# PIC32MK0512GPG048 device description
Architecture: MIPS; Family: PIC32MK; Series: PIC32MK
Registers are 32-bit, read-write, no defined reset value unless marked. A register's access mark holds for its fields unless they carry their own. Offsets are from the block's base; [hi:lo] are bit positions; {n}, {i} and the like mark numbered series.

## DMT
Instances: DMT 0x1f800e00 in periph_pb1_std
0x00 DMTCON — Deadman Timer Control Register
  [15] ON — Deadman Timer Module Enable bit
    1=Deadman Timer module is enabled; 0=Deadman Timer module is disabled
0x10 DMTPRECLR — Deadman Timer Preclear Register
  [15:8] STEP1 — Preclear Enable bits
    64=Enables the Deadman Timer Preclear (Step 1)
0x20 DMTCLR — Deadman Timer Clear Register
  [7:0] STEP2 — Clear Timer bits
    8=Clears STEP1
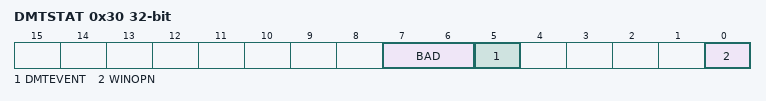
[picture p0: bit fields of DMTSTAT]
0x30 DMTSTAT ro — Deadman Timer Status Register
  [7:6] BAD — Bad STEP2 Value Detect bit
    3=Incorrect STEP1 value was detected/Incorrect STEP2 value was detected; 2=Incorrect STEP1 value was detected/Incorrect STEP2 value was not detected; 1=Incorrect STEP1 value was not detected/Incorrect STEP2 value was detected; 0=Incorrect STEP1 value was not detected/Incorrect STEP2 value was not detected
  [5] DMTEVENT — Deadman Timer Event bit
    1=Deadman timer event was detected (counter expired or bad STEP1 or STEP2 value was entered prior to counter increment); 0=Deadman timer even was not detected
  [0] WINOPN — Deadman Timer Clear Window bit
    1=Deadman timer clear window is open; 0=Deadman timer clear window is not open
0x40 DMTCNT ro — Deadman Timer Count Register
  [31:0] COUNTER
0x60 DMTPSCNT ro — Post Status Configure DMT Count Status Register
  [31:0] PSCNT
0x70 DMTPSINTV ro — Post Status Configure DMT Interval Status Register
  [31:0] PSINTV
Value list DMTSTAT__BAD1: 1=Incorrect STEP1 value was detected; 0=Incorrect STEP1 value was not detected

## DSCTRL
Instances: DSCTRL 0x1f8c0200 in periph_pb6_std
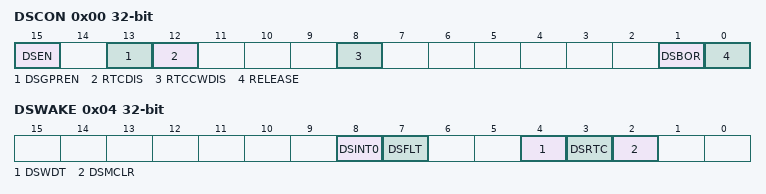
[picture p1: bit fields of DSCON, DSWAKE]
0x00 DSCON — Deep Sleep Control Register
  [15] DSEN — Deep Sleep Enable bit
    1=Deep Sleep mode is entered on a WAIT command; 0=Sleep mode is entered on a WAIT command
  [13] DSGPREN — General Purpose Registers Enable bit
    1=General purpose register retention is enabled in Deep Sleep mode; 0=No general purpose register retention in Deep Sleep mode
  [12] RTCDIS — RTCC Module Disable bit
    1=RTCC module is not enabled; 0=RTCC module is enabled
  [8] RTCCWDIS — RTCC Wake-up Disable bit
    1=Wake-up from RTCC is disabled; 0=Wake-up from RTCC is enabled
  [1] DSBOR — Deep Sleep BOR Event Status bit
    1=DSBOREN was enabled and VDD dropped below the DSBOR threshold during Deep Sleep; 0=DSBOREN was disabled, or VDD did not drop below the DSBOR threshold during Deep Sleep
  [0] RELEASE — I/O Pin State Release bit
    1=Upon waking from Deep Sleep, the I/O pins maintain their previous states; 0=Release I/O pins and allow their respective TRIS and LAT bits to control their states
0x04 DSWAKE — Deep Sleep Wake-up Source Register
  [8] DSINT0 — Interrupt-on-Change bit
    1=Interrupt-on-change was asserted during Deep Sleep; 0=Interrupt-on-change was not asserted during Deep Sleep
  [7] DSFLT — Deep Sleep Fault Detected bit
    1=A Fault occurred during Deep Sleep and some Deep Sleep configuration settings may have been corrupted; 0=No Fault was detected during Deep Sleep
  [4] DSWDT — Deep Sleep Watchdog Timer Time-out bit
    1=The Deep Sleep Watchdog Timer timed out during Deep Sleep; 0=The Deep Sleep Watchdog Timer did not time-out during Deep Sleep
  [3] DSRTC — Real-Time Clock and Calendar Alarm bit
    1=The Real-Time Clock and Calendar triggered an alarm during Deep Sleep; 0=The Real-Time Clock and Calendar did not trigger an alarm during Deep Sleep
  [2] DSMCLR — MCLR Event bit
    1=The MCLR pin was active and was asserted during Deep Sleep; 0=The MCLR pin was not active, or was active, but not asserted during Deep Sleep
0x08 DSGPR0
  [31:0] DSGPR
{0xC+4i} DSGPR{i} (i=1..32)
  [31:0] DSGPR

## HLVD
Instances: HLVD 0x1f801800 in periph_pb1_std
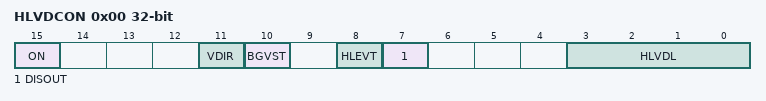
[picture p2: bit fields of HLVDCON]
0x00 HLVDCON — High/Low-Voltage Detect Control Register
  [15] ON — HLVD Module Enable bit
    1=HLVD module is enabled; 0=HLVD module is disabled
  [11] VDIR — Voltage Change Direction Select bit
    1=Event occurs when voltage equals or exceeds the trip point (HLVDL); 0=Event occurs when voltage equals or falls below the trip point (HLVDL)
  [10] BGVST — Band Gap Reference Voltages Stable Status bit
    1=Indicates internal band gap voltage references is stable; 0=Indicates internal band gap voltage reference is not stable
  [8] HLEVT — High/Low-Voltage Detection Event Status bit
    1=Indicates HLVD Event is active; 0=Indicates HLVD Event is not active
  [7] DISOUT — Disable HLVD Output bit
    1=Enable output of HLVD Comparator. Once set, can only be cleared by setting the ON bit to 0.; 0=Disable output of HLVD Comparator (default Reset value)
  [3:0] HLVDL — High/Low-Voltage Detection Limit Select bits
    15=1.2V (Selects external LVDIN pin); 10=2.4V; 9=2.5V; 8=2.69V; 7=2.791V; 6=3.0V; 5=3.288V; 4=3.529V

## Notices in the file
Copyright (c) 2019 Microchip Technology Inc.
SPDX-License-Identifier: Apache-2.0
Licensed under the Apache License, Version 2.0 (the "License");
you may not use this file except in compliance with the License.
You may obtain a copy of the License at
http://www.apache.org/licenses/LICENSE-2.0
Unless required by applicable law or agreed to in writing, software
distributed under the License is distributed on an "AS IS" BASIS,
WITHOUT WARRANTIES OR CONDITIONS OF ANY KIND, either express or implied.
See the License for the specific language governing permissions and
limitations under the License.
